# Battery_Charger_1 register map
Vendor: Texas Instruments
Peripheral module from a debugger description file (folder msp430).
Registers are 16-bit, read-write, reset 0x0 unless marked. A register's access mark holds for its fields unless they carry their own. Offsets are as the file gives them; lines under a group give offsets from that group; [hi:lo] are bit positions; {n}, {i} and the like mark numbered series; 'fields as' and 'values as' point back to an identical list; <NAME> marks a mode.

## Battery_Charger
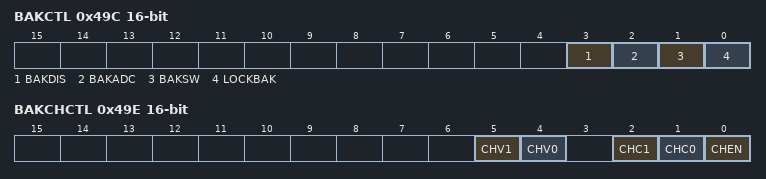
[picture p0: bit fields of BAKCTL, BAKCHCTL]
0x49C BAKCTL — Battery Backup Control
  [3] BAKDIS — Disable backup supply switching.
  [2] BAKADC — Battery backup supply to ADC.
  [1] BAKSW — Manual switch to battery backup supply
  [0] LOCKBAK — Lock backup sub-system
0x49E BAKCHCTL — Battery Charger Control
  [5] CHV1 — Charger end voltage Bit 1
  [4] CHV0 — Charger end voltage Bit 0
  [2] CHC1 — Charger charge current Bit 1
  [1] CHC0 — Charger charge current Bit 0
  [0] CHEN — Charger enable
